# D2522AA register map
Vendor: Dialog; Series: D2522AA; File version: 1.2
CPU: CM0 r1p0, little endian, MPU, FPU, 3 interrupt priority bits
Registers are 32-bit, read-write, reset 0x0 unless marked. A register's access mark holds for its fields unless they carry their own. Offsets are from the block's base; [hi:lo] are bit positions.

## I2C2 — I2C2 registers
Base 0x50020700
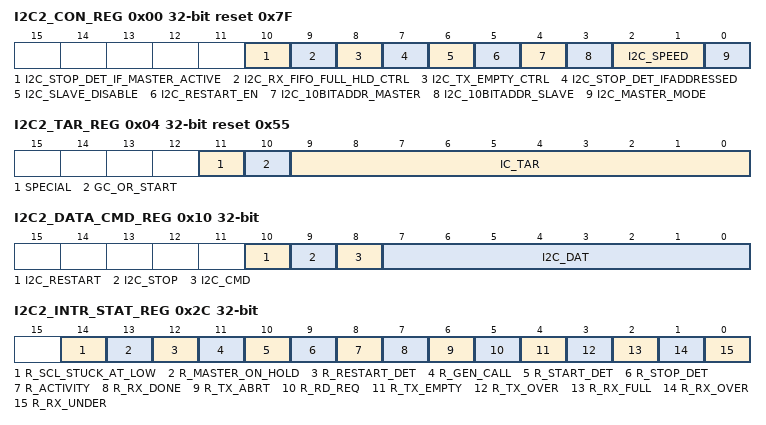
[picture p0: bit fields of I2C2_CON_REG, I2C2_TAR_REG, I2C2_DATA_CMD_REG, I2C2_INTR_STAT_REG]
0x00 I2C2_CON_REG reset 0x7F — I2C Control Register
  [10] I2C_STOP_DET_IF_MASTER_ACTIVE ro — In Master mode: 1 = issues the STOP_DET interrupt only when master is active. 0 = issues the STOP_DET irrespective of whether master is active or not.
  [9] I2C_RX_FIFO_FULL_HLD_CTRL — This bit controls whether DW_apb_i2c should hold the bus when the Rx FIFO is physically full to its RX_BUFFER_DEPTH 1 = Hold bus when RX_FIFO is full 0 = Overflow when RX_FIFO is full
  [8] I2C_TX_EMPTY_CTRL — This bit controls the generation of the TX_EMPTY interrupt, as described in the IC_RAW_INTR_STAT register. 1 = Controlled generation of TX_EMPTY interrupt 0 = Default behaviour of TX_EMPTY interrupt
  [7] I2C_STOP_DET_IFADDRESSED — 1 = slave issues STOP_DET intr only if addressed 0 = slave issues STOP_DET intr always During a general call address, this slave does not issue the STOP_DET interrupt if STOP_DET_IF_ADDRESSED = 1'b1, even if the slave responds to the general call address by generating ACK. The STOP_DET interrupt is generated only when the transmitted address matches the slave address (SAR).
  [6] I2C_SLAVE_DISABLE — Slave enabled or disabled after reset is applied, which means software does not have to configure the slave. 0=slave is enabled 1=slave is disabled Software should ensure that if this bit is written with '0', then bit 0 should also be written with a '0'.
  [5] I2C_RESTART_EN — Determines whether RESTART conditions may be sent when acting as a master 0= disable 1=enable
  [4] I2C_10BITADDR_MASTER — Controls whether the controller starts its transfers in 7- or 10-bit addressing mode when acting as a master. 0= 7-bit addressing 1= 10-bit addressing
  [3] I2C_10BITADDR_SLAVE — When acting as a slave, this bit controls whether the controller responds to 7- or 10-bit addresses. 0= 7-bit addressing 1= 10-bit addressing
  [2:1] I2C_SPEED — These bits control at which speed the controller operates. 1= standard mode (100 kbit/s) 2= fast mode (400 kbit/s) 3= high speed mode
  [0] I2C_MASTER_MODE — This bit controls whether the controller master is enabled. 0= master disabled 1= master enabled Software should ensure that if this bit is written with '1' then bit 6 should also be written with a '1'.
0x04 I2C2_TAR_REG reset 0x55 — I2C Target Address Register
  [11] SPECIAL — On read This bit indicates whether software performs a General Call or START BYTE command. 0 = ignore bit 10 GC_OR_START and use IC_TAR normally 1 = perform special I2C command as specified in GC_OR_START bit On write 1 = Enables programming of GENERAL_CALL or START_BYTE transmission 0 = Disables programming of GENERAL_CALL or START_BYTE transmission
  [10] GC_OR_START — On read If bit 11 (SPECIAL) is set to 1, then this bit indicates whether a General Call or START byte command is to be performed by the controller. 0 = General Call Address - after issuing a General Call, only writes may be performed. Attempting to issue a read command results in setting bit 6 (TX_ABRT) of the IC_RAW_INTR_STAT register. The controller remains in General Call mode until the SPECIAL bit value (bit 11) is cleared. 1 = START BYTE On write 1 = START byte transmission 0 = GENERAL_CALL byte transmission
  [9:0] IC_TAR — This is the target address for any master transaction. When transmitting a General Call, these bits are ignored. To generate a START BYTE, the CPU needs to write only once into these bits. Note: If the IC_TAR and IC_SAR are the same, loopback exists but the FIFOs are shared between master and slave, so full loopback is not feasible. Only one direction loopback mode is supported (simplex), not duplex. A master cannot transmit to itself; it can transmit to only a slave
0x08 I2C2_SAR_REG reset 0x55 — I2C Slave Address Register
  [9:0] IC_SAR — The IC_SAR holds the slave address when the I2C is operating as a slave. For 7-bit addressing, only IC_SAR[6:0] is used. This register can be written only when the I2C interface is disabled, which corresponds to the IC_ENABLE register being set to 0. Writes at other times have no effect.
0x0C I2C2_HS_MADDR_REG reset 0x1 — I2C High Speed Master Mode Code Address Register
  [2:0] I2C_IC_HS_MAR — This bit field holds the value of the I2C HS mode master code. HS-mode master codes are reserved 8-bit codes (00001xxx) that are not used for slave addressing or other purposes. Each master has its unique master code; up to eight high-speed mode masters can be present on the same I2C bus system. Valid values are from 0 to 7. This register can be written only when the I2C interface is disabled, which corresponds to the IC_ENABLE[0] register being set to 0. Writes at other times have no effect.
0x10 I2C2_DATA_CMD_REG — I2C Rx/Tx Data Buffer and Command Register
  [10] I2C_RESTART wo — This bit controls whether a RESTART is issued before the byte is sent or received. 1 = If IC_RESTART_EN is 1, a RESTART is issued before the data is sent/received (according to the value of CMD), regardless of whether or not the transfer direction is changing from the previous command; if IC_RESTART_EN is 0, a STOP followed by a START is issued instead. 0 = If IC_RESTART_EN is 1, a RESTART is issued only if the transfer direction is changing from the previous command; if IC_RESTART_EN is 0, a STOP followed by a START is issued instead.
  [9] I2C_STOP wo — This bit controls whether a STOP is issued after the byte is sent or received. 1 = STOP is issued after this byte, regardless of whether or not the Tx FIFO is empty. If the Tx FIFO is not empty, the master immediately tries to start a new transfer by issuing a START and arbitrating for the bus. 0 = STOP is not issued after this byte, regardless of whether or not the Tx FIFO is empty. If the Tx FIFO is not empty, the master continues the current transfer by sending/receiving data bytes according to the value of the CMD bit. If the Tx FIFO is empty, the master holds the SCL line low and stalls the bus until a new command is available in the Tx FIFO.
  [8] I2C_CMD wo — This bit controls whether a read or a write is performed. This bit does not control the direction when the I2C Ctrl acts as a slave. It controls only the direction when it acts as a master. 1 = Read 0 = Write When a command is entered in the TX FIFO, this bit distinguishes the write and read commands. In slave-receiver mode, this bit is a "don't care" because writes to this register are not required. In slave-transmitter mode, a "0" indicates that CPU data is to be transmitted and as DAT or IC_DATA_CMD[7:0]. When programming this bit, you should remember the following: attempting to perform a read operation after a General Call command has been sent results in a TX_ABRT interrupt (bit 6 of the I2C_RAW_INTR_STAT_REG), unless bit 11 (SPECIAL) in the I2C_TAR register has been cleared. If a "1" is written to this bit after receiving a RD_REQ interrupt, then a TX_ABRT interrupt occurs. NOTE: It is possible that while attempting a master I2C read transfer on the controller, a RD_REQ interrupt may have occurred simultaneously due to a remote I2C master addressing the controller. In this type of scenario, it ignores the I2C_DATA_CMD write, generates a TX_ABRT interrupt, and waits to service the RD_REQ interrupt
  [7:0] I2C_DAT — This register contains the data to be transmitted or received on the I2C bus. If you are writing to this register and want to perform a read, bits 7:0 (DAT) are ignored by the controller. However, when you read this register, these bits return the value of data received on the controller's interface.
0x14 I2C2_SS_SCL_HCNT_REG reset 0x91 — Standard Speed I2C Clock SCL High Count Register
  [15:0] IC_SS_SCL_HCNT — This register must be set before any I2C bus transaction can take place to ensure proper I/O timing. This register sets the SCL clock high-period count for standard speed. This register can be written only when the I2C interface is disabled which corresponds to the IC_ENABLE register being set to 0. Writes at other times have no effect. The minimum valid value is 6; hardware prevents values less than this being written, and if attempted results in 6 being set. NOTE: This register must not be programmed to a value higher than 65525, because the controller uses a 16-bit counter to flag an I2C bus idle condition when this counter reaches a value of IC_SS_SCL_HCNT + 10.
0x18 I2C2_SS_SCL_LCNT_REG reset 0xAB — Standard Speed I2C Clock SCL Low Count Register
  [15:0] IC_SS_SCL_LCNT — This register must be set before any I2C bus transaction can take place to ensure proper I/O timing. This register sets the SCL clock low period count for standard speed. This register can be written only when the I2C interface is disabled which corresponds to the I2C_ENABLE register being set to 0. Writes at other times have no effect. The minimum valid value is 8; hardware prevents values less than this being written, and if attempted, results in 8 being set.
0x1C I2C2_FS_SCL_HCNT_REG reset 0x1A — Fast Speed I2C Clock SCL High Count Register
  [15:0] IC_FS_SCL_HCNT — This register must be set before any I2C bus transaction can take place to ensure proper I/O timing. This register sets the SCL clock high-period count for fast speed. It is used in high-speed mode to send the Master Code and START BYTE or General CALL. This register can be written only when the I2C interface is disabled, which corresponds to the I2C_ENABLE register being set to 0. Writes at other times have no effect. The minimum valid value is 6; hardware prevents values less than this being written, and if attempted results in 6 being set.
0x20 I2C2_FS_SCL_LCNT_REG reset 0x32 — Fast Speed I2C Clock SCL Low Count Register
  [15:0] IC_FS_SCL_LCNT — This register must be set before any I2C bus transaction can take place to ensure proper I/O timing. This register sets the SCL clock low-period count for fast speed. It is used in high-speed mode to send the Master Code and START BYTE or General CALL. This register can be written only when the I2C interface is disabled, which corresponds to the I2C_ENABLE register being set to 0. Writes at other times have no effect. The minimum valid value is 8; hardware prevents values less than this being written, and if attempted results in 8 being set. For designs with APB_DATA_WIDTH = 8 the order of programming is important to ensure the correct operation of the controller. The lower byte must be programmed first. Then the upper byte is programmed.
0x24 I2C2_HS_SCL_HCNT_REG reset 0x6 — High Speed I2C Clock SCL High Count Register
  [15:0] IC_HS_SCL_HCNT — This register must be set before any I2C bus transaction can take place to ensure proper I/O timing. This register sets the SCL clock high period count for high speed.refer to "IC_CLK Frequency Configuration". The SCL High time depends on the loading of the bus. For 100pF loading, the SCL High time is 60ns; for 400pF loading, the SCL High time is 120ns. This register goes away and becomes read-only returning 0s if IC_MAX_SPEED_MODE != high. This register can be written only when the I2C interface is disabled, which corresponds to the IC_ENABLE[0] register being set to 0. Writes at other times have no effect. The minimum valid value is 6; hardware prevents values less than this being written, and if attempted results in 6 being set. For designs with APB_DATA_WIDTH = 8 the order of programming is important to ensure the correct operation of the DW_apb_i2c. The lower byte must be programmed first. Then the upper byte is programmed.
0x28 I2C2_HS_SCL_LCNT_REG reset 0x10 — High Speed I2C Clock SCL Low Count Register
  [15:0] IC_HS_SCL_LCNT — This register must be set before any I2C bus transaction can take place to ensure proper I/O timing. This register sets the SCL clock low period count for high speed. For more information, refer to "IC_CLK Frequency Configuration". The SCL low time depends on the loading of the bus. For 100pF loading, the SCL low time is 160ns; for 400pF loading, the SCL low time is 320ns. This register goes away and becomes read-only returning 0s if IC_MAX_SPEED_MODE != high. This register can be written only when the I2C interface is disabled, which corresponds to the IC_ENABLE[0] register being set to 0. Writes at other times have no effect. The minimum valid value is 8; hardware prevents values less than this being written, and if attempted results in 8 being set. For designs with APB_DATA_WIDTH == 8 the order of programming is important to ensure the correct operation of the DW_apb_i2c. The lower byte must be programmed first. Then the upper byte is programmed. If the value is less than 8 then the count value gets changed to 8.
0x2C I2C2_INTR_STAT_REG — I2C Interrupt Status Register
  [14] R_SCL_STUCK_AT_LOW ro — 1 = R_SCL_STUCK_AT_LOW interrupt is active 0 = R_SCL_STUCK_AT_LOW interrupt is inactive
  [13] R_MASTER_ON_HOLD ro — Indicates whether master is holding the bus and TX FIFO is empty. Enabled only when I2C_DYNAMIC_TAR_UPDATE=1 and IC_EMPTYFIFO_HOLD_MASTER_EN=1.
  [12] R_RESTART_DET ro — Indicates whether a RESTART condition has occurred on the I2C interface when DW_apb_i2c is operating in Slave mode and the slave is being addressed. Enabled only when IC_SLV_RESTART_DET_EN=1. Note: However, in high-speed mode or during a START BYTE transfer, the RESTART comes before the address field as per the I2C protocol. In this case, the slave is not the addressed slave when the RESTART is issued, therefore DW_apb_i2c does not generate the RESTART_DET interrupt.
  [11] R_GEN_CALL ro — Set only when a General Call address is received and it is acknowledged. It stays set until it is cleared either by disabling controller or when the CPU reads bit 0 of the I2C_CLR_GEN_CALL register. The controller stores the received data in the Rx buffer.
  [10] R_START_DET ro — Indicates whether a START or RESTART condition has occurred on the I2C interface regardless of whether controller is operating in slave or master mode.
  [9] R_STOP_DET ro — Indicates whether a STOP condition has occurred on the I2C interface regardless of whether controller is operating in slave or master mode.
  [8] R_ACTIVITY ro — This bit captures I2C Ctrl activity and stays set until it is cleared. There are four ways to clear it: => Disabling the I2C Ctrl => Reading the IC_CLR_ACTIVITY register => Reading the IC_CLR_INTR register => System reset Once this bit is set, it stays set unless one of the four methods is used to clear it. Even if the controller module is idle, this bit remains set until cleared, indicating that there was activity on the bus.
  [7] R_RX_DONE ro — When the controller is acting as a slave-transmitter, this bit is set to 1 if the master does not acknowledge a transmitted byte. This occurs on the last byte of the transmission, indicating that the transmission is done.
  [6] R_TX_ABRT ro — This bit indicates if the controller, as an I2C transmitter, is unable to complete the intended actions on the contents of the transmit FIFO. This situation can occur both as an I2C master or an I2C slave, and is referred to as a "transmit abort". When this bit is set to 1, the I2C_TX_ABRT_SOURCE register indicates the reason why the transmit abort takes places. NOTE: The controller flushes/resets/empties the TX FIFO whenever this bit is set. The TX FIFO remains in this flushed state until the register I2C_CLR_TX_ABRT is read. Once this read is performed, the TX FIFO is then ready to accept more data bytes from the APB interface.
  [5] R_RD_REQ ro — This bit is set to 1 when the controller is acting as a slave and another I2C master is attempting to read data from the controller. The controller holds the I2C bus in a wait state (SCL=0) until this interrupt is serviced, which means that the slave has been addressed by a remote master that is asking for data to be transferred. The processor must respond to this interrupt and then write the requested data to the I2C_DATA_CMD register. This bit is set to 0 just after the processor reads the I2C_CLR_RD_REQ register
  [4] R_TX_EMPTY ro — This bit is set to 1 when the transmit buffer is at or below the threshold value set in the I2C_TX_TL register. It is automatically cleared by hardware when the buffer level goes above the threshold. When the IC_ENABLE bit 0 is 0, the TX FIFO is flushed and held in reset. There the TX FIFO looks like it has no data within it, so this bit is set to 1, provided there is activity in the master or slave state machines. When there is no longer activity, then with ic_en=0, this bit is set to 0.
  [3] R_TX_OVER ro — Set during transmit if the transmit buffer is filled to 32 and the processor attempts to issue another I2C command by writing to the IC_DATA_CMD register. When the module is disabled, this bit keeps its level until the master or slave state machines go into idle, and when ic_en goes to 0, this interrupt is cleared
  [2] R_RX_FULL ro — Set when the receive buffer reaches or goes above the RX_TL threshold in the I2C_RX_TL register. It is automatically cleared by hardware when buffer level goes below the threshold. If the module is disabled (I2C_ENABLE[0]=0), the RX FIFO is flushed and held in reset; therefore the RX FIFO is not full. So this bit is cleared once the I2C_ENABLE bit 0 is programmed with a 0, regardless of the activity that continues.
  [1] R_RX_OVER ro — Set if the receive buffer is completely filled to 32 and an additional byte is received from an external I2C device. The controller acknowledges this, but any data bytes received after the FIFO is full are lost. If the module is disabled (I2C_ENABLE[0]=0), this bit keeps its level until the master or slave state machines go into idle, and when ic_en goes to 0, this interrupt is cleared.
  [0] R_RX_UNDER ro — Set if the processor attempts to read the receive buffer when it is empty by reading from the IC_DATA_CMD register. If the module is disabled (I2C_ENABLE[0]=0), this bit keeps its level until the master or slave state machines go into idle, and when ic_en goes to 0, this interrupt is cleared.
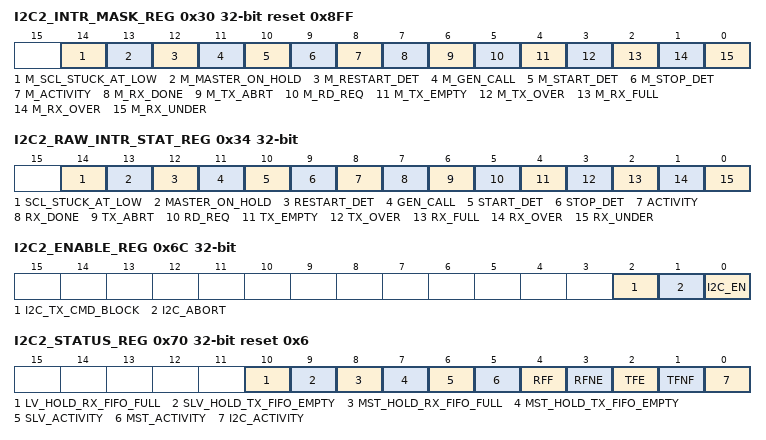
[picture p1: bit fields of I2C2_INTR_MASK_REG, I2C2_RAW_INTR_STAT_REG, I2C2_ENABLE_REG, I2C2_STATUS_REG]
0x30 I2C2_INTR_MASK_REG reset 0x8FF — I2C Interrupt Mask Register
  [14] M_SCL_STUCK_AT_LOW ro — M_SCL_STUCK_AT_LOW Register field Reserved bits
  [13] M_MASTER_ON_HOLD — These bits mask their corresponding interrupt status bits in the I2C_INTR_STAT register.
  [12] M_RESTART_DET — These bits mask their corresponding interrupt status bits in the I2C_INTR_STAT register.
  [11] M_GEN_CALL — These bits mask their corresponding interrupt status bits in the I2C_INTR_STAT register.
  [10] M_START_DET — These bits mask their corresponding interrupt status bits in the I2C_INTR_STAT register.
  [9] M_STOP_DET — These bits mask their corresponding interrupt status bits in the I2C_INTR_STAT register.
  [8] M_ACTIVITY — These bits mask their corresponding interrupt status bits in the I2C_INTR_STAT register.
  [7] M_RX_DONE — These bits mask their corresponding interrupt status bits in the I2C_INTR_STAT register.
  [6] M_TX_ABRT — These bits mask their corresponding interrupt status bits in the I2C_INTR_STAT register.
  [5] M_RD_REQ — These bits mask their corresponding interrupt status bits in the I2C_INTR_STAT register.
  [4] M_TX_EMPTY — These bits mask their corresponding interrupt status bits in the I2C_INTR_STAT register.
  [3] M_TX_OVER — These bits mask their corresponding interrupt status bits in the I2C_INTR_STAT register.
  [2] M_RX_FULL — These bits mask their corresponding interrupt status bits in the I2C_INTR_STAT register.
  [1] M_RX_OVER — These bits mask their corresponding interrupt status bits in the I2C_INTR_STAT register.
  [0] M_RX_UNDER — These bits mask their corresponding interrupt status bits in the I2C_INTR_STAT register.
0x34 I2C2_RAW_INTR_STAT_REG — I2C Raw Interrupt Status Register
  [14] SCL_STUCK_AT_LOW ro — CL_STUCK_AT_LOW Register field Reserved bits
  [13] MASTER_ON_HOLD ro — ndicates whether master is holding the bus and TX FIFO is empty. Enabled only when I2C_DYNAMIC_TAR_UPDATE=1 and IC_EMPTYFIFO_HOLD_MASTER_EN=1.
  [12] RESTART_DET ro — Indicates whether a RESTART condition has occurred on the I2C interface when DW_apb_i2c is operating in Slave mode and the slave is being addressed. Enabled only when IC_SLV_RESTART_DET_EN=1. Note: However, in high-speed mode or during a START BYTE transfer, the RESTART comes before the address field as per the I2C protocol. In this case, the slave is not the addressed slave when the RESTART is issued, therefore DW_apb_i2c does not generate the RESTART_DET interrupt.
  [11] GEN_CALL ro — Set only when a General Call address is received and it is acknowledged. It stays set until it is cleared either by disabling controller or when the CPU reads bit 0 of the I2C_CLR_GEN_CALL register. I2C Ctrl stores the received data in the Rx buffer.
  [10] START_DET ro — Indicates whether a START or RESTART condition has occurred on the I2C interface regardless of whether controller is operating in slave or master mode.
  [9] STOP_DET ro — Indicates whether a STOP condition has occurred on the I2C interface regardless of whether controller is operating in slave or master mode.
  [8] ACTIVITY ro — This bit captures I2C Ctrl activity and stays set until it is cleared. There are four ways to clear it: => Disabling the I2C Ctrl => Reading the IC_CLR_ACTIVITY register => Reading the IC_CLR_INTR register => System reset Once this bit is set, it stays set unless one of the four methods is used to clear it. Even if the controller module is idle, this bit remains set until cleared, indicating that there was activity on the bus.
  [7] RX_DONE ro — When the controller is acting as a slave-transmitter, this bit is set to 1 if the master does not acknowledge a transmitted byte. This occurs on the last byte of the transmission, indicating that the transmission is done.
  [6] TX_ABRT ro — This bit indicates if the controller, as an I2C transmitter, is unable to complete the intended actions on the contents of the transmit FIFO. This situation can occur both as an I2C master or an I2C slave, and is referred to as a "transmit abort". When this bit is set to 1, the I2C_TX_ABRT_SOURCE register indicates the reason why the transmit abort takes places. NOTE: The controller flushes/resets/empties the TX FIFO whenever this bit is set. The TX FIFO remains in this flushed state until the register I2C_CLR_TX_ABRT is read. Once this read is performed, the TX FIFO is then ready to accept more data bytes from the APB interface.
  [5] RD_REQ ro — This bit is set to 1 when I2C Ctrl is acting as a slave and another I2C master is attempting to read data from the controller. The controller holds the I2C bus in a wait state (SCL=0) until this interrupt is serviced, which means that the slave has been addressed by a remote master that is asking for data to be transferred. The processor must respond to this interrupt and then write the requested data to the I2C_DATA_CMD register. This bit is set to 0 just after the processor reads the I2C_CLR_RD_REQ register
  [4] TX_EMPTY ro — This bit is set to 1 when the transmit buffer is at or below the threshold value set in the I2C_TX_TL register. It is automatically cleared by hardware when the buffer level goes above the threshold. When the IC_ENABLE bit 0 is 0, the TX FIFO is flushed and held in reset. There the TX FIFO looks like it has no data within it, so this bit is set to 1, provided there is activity in the master or slave state machines. When there is no longer activity, then with ic_en=0, this bit is set to 0.
  [3] TX_OVER ro — Set during transmit if the transmit buffer is filled to 32 and the processor attempts to issue another I2C command by writing to the IC_DATA_CMD register. When the module is disabled, this bit keeps its level until the master or slave state machines go into idle, and when ic_en goes to 0, this interrupt is cleared
  [2] RX_FULL ro — Set when the receive buffer reaches or goes above the RX_TL threshold in the I2C_RX_TL register. It is automatically cleared by hardware when buffer level goes below the threshold. If the module is disabled (I2C_ENABLE[0]=0), the RX FIFO is flushed and held in reset; therefore the RX FIFO is not full. So this bit is cleared once the I2C_ENABLE bit 0 is programmed with a 0, regardless of the activity that continues.
  [1] RX_OVER ro — Set if the receive buffer is completely filled to 32 and an additional byte is received from an external I2C device. The controller acknowledges this, but any data bytes received after the FIFO is full are lost. If the module is disabled (I2C_ENABLE[0]=0), this bit keeps its level until the master or slave state machines go into idle, and when ic_en goes to 0, this interrupt is cleared.
  [0] RX_UNDER ro — Set if the processor attempts to read the receive buffer when it is empty by reading from the IC_DATA_CMD register. If the module is disabled (I2C_ENABLE[0]=0), this bit keeps its level until the master or slave state machines go into idle, and when ic_en goes to 0, this interrupt is cleared.
0x38 I2C2_RX_TL_REG — I2C Receive FIFO Threshold Register
  [4:0] RX_TL — Receive FIFO Threshold Level Controls the level of entries (or above) that triggers the RX_FULL interrupt (bit 2 in I2C_RAW_INTR_STAT register). The valid range is 0-31, with the additional restriction that hardware does not allow this value to be set to a value larger than the depth of the buffer. If an attempt is made to do that, the actual value set will be the maximum depth of the buffer. A value of 0 sets the threshold for 1 entry, and a value of 31 sets the threshold for 32 entries.
0x3C I2C2_TX_TL_REG — I2C Transmit FIFO Threshold Register
  [4:0] TX_TL — Transmit FIFO Threshold Level Controls the level of entries (or below) that trigger the TX_EMPTY interrupt (bit 4 in I2C_RAW_INTR_STAT register). The valid range is 0-31, with the additional restriction that it may not be set to value larger than the depth of the buffer. If an attempt is made to do that, the actual value set will be the maximum depth of the buffer. A value of 0 sets the threshold for 0 entries, and a value of 31 sets the threshold for 32 entries..
0x40 I2C2_CLR_INTR_REG — Clear Combined and Individual Interrupt Register
  [0] CLR_INTR ro — Read this register to clear the combined interrupt, all individual interrupts, and the I2C_TX_ABRT_SOURCE register. This bit does not clear hardware clearable interrupts but software clearable interrupts. Refer to Bit 9 of the I2C_TX_ABRT_SOURCE register for an exception to clearing I2C_TX_ABRT_SOURCE
0x44 I2C2_CLR_RX_UNDER_REG — Clear RX_UNDER Interrupt Register
  [0] CLR_RX_UNDER ro — Read this register to clear the RX_UNDER interrupt (bit 0) of the I2C_RAW_INTR_STAT register.
0x48 I2C2_CLR_RX_OVER_REG — Clear RX_OVER Interrupt Register
  [0] CLR_RX_OVER ro — Read this register to clear the RX_OVER interrupt (bit 1) of the I2C_RAW_INTR_STAT register.
0x4C I2C2_CLR_TX_OVER_REG — Clear TX_OVER Interrupt Register
  [0] CLR_TX_OVER ro — Read this register to clear the TX_OVER interrupt (bit 3) of the I2C_RAW_INTR_STAT register.
0x50 I2C2_CLR_RD_REQ_REG — Clear RD_REQ Interrupt Register
  [0] CLR_RD_REQ ro — Read this register to clear the RD_REQ interrupt (bit 5) of the I2C_RAW_INTR_STAT register.
0x54 I2C2_CLR_TX_ABRT_REG — Clear TX_ABRT Interrupt Register
  [0] CLR_TX_ABRT ro — Read this register to clear the TX_ABRT interrupt (bit 6) of the IC_RAW_INTR_STAT register, and the I2C_TX_ABRT_SOURCE register. This also releases the TX FIFO from the flushed/reset state, allowing more writes to the TX FIFO. Refer to Bit 9 of the I2C_TX_ABRT_SOURCE register for an exception to clearing IC_TX_ABRT_SOURCE.
0x58 I2C2_CLR_RX_DONE_REG — Clear RX_DONE Interrupt Register
  [0] CLR_RX_DONE ro — Read this register to clear the RX_DONE interrupt (bit 7) of the I2C_RAW_INTR_STAT register.
0x5C I2C2_CLR_ACTIVITY_REG — Clear ACTIVITY Interrupt Register
  [0] CLR_ACTIVITY ro — Reading this register clears the ACTIVITY interrupt if the I2C is not active anymore. If the I2C module is still active on the bus, the ACTIVITY interrupt bit continues to be set. It is automatically cleared by hardware if the module is disabled and if there is no further activity on the bus. The value read from this register to get status of the ACTIVITY interrupt (bit 8) of the IC_RAW_INTR_STAT register
0x60 I2C2_CLR_STOP_DET_REG — Clear STOP_DET Interrupt Register
  [0] CLR_ACTIVITY ro — Reading this register clears the ACTIVITY interrupt if the I2C is not active anymore. If the I2C module is still active on the bus, the ACTIVITY interrupt bit continues to be set. It is automatically cleared by hardware if the module is disabled and if there is no further activity on the bus. The value read from this register to get status of the ACTIVITY interrupt (bit 8) of the IC_RAW_INTR_STAT register.
0x64 I2C2_CLR_START_DET_REG — Clear START_DET Interrupt Register
  [0] CLR_START_DET ro — Read this register to clear the START_DET interrupt (bit 10) of the IC_RAW_INTR_STAT register.
0x68 I2C2_CLR_GEN_CALL_REG — Clear GEN_CALL Interrupt Register
  [0] CLR_GEN_CALL ro — Read this register to clear the GEN_CALL interrupt (bit 11) of I2C_RAW_INTR_STAT register.
0x6C I2C2_ENABLE_REG — I2C Enable Register
  [2] I2C_TX_CMD_BLOCK — In Master mode: 1 = Blocks the transmission of data on I2C bus even if Tx FIFO has data to transmit. 0.= The transmission of data starts on I2C bus automatically, as soon as the first data is available in the Tx FIFO.
  [1] I2C_ABORT — The software can abort the I2C transfer in master mode by setting this bit. The software can set this bit only when ENABLE is already set; otherwise, the controller ignores any write to ABORT bit. The software cannot clear the ABORT bit once set. In response to an ABORT, the controller issues a STOP and flushes the Tx FIFO after completing the current transfer, then sets the TX_ABORT interrupt after the abort operation. The ABORT bit is cleared automatically after the abort operation.
  [0] I2C_EN — Controls whether the controller is enabled. 0 = Disables the controller (TX and RX FIFOs are held in an erased state) 1 = Enables the controller Software can disable the controller while it is active. However, it is important that care be taken to ensure that the controller is disabled properly. When the controller is disabled, the following occurs: * The TX FIFO and RX FIFO get flushed. * Status bits in the IC_INTR_STAT register are still active until the controller goes into IDLE state. If the module is transmitting, it stops as well as deletes the contents of the transmit buffer after the current transfer is complete. If the module is receiving, the controller stops the current transfer at the end of the current byte and does not acknowledge the transfer. There is a two ic_clk delay when enabling or disabling the controller
0x70 I2C2_STATUS_REG reset 0x6 — I2C Status Register
  [10] LV_HOLD_RX_FIFO_FULL ro — This bit indicates the BUS Hold in Slave mode due to Rx FIFO is Full and an additional byte has been received 1 = Slave holds the bus due to Rx FIFO is full 0 = Slave is not holding the bus or Bus hold is not due to Rx FIFO is full
  [9] SLV_HOLD_TX_FIFO_EMPTY ro — This bit indicates the BUS Hold in Slave mode for the Read request when the Tx FIFO is empty. The Bus is in hold until the Tx FIFO has data to Transmit for the read request. 1 = Slave holds the bus due to Tx FIFO is empty 0 = Slave is not holding the bus or Bus hold is not due to Tx FIFO is empty
  [8] MST_HOLD_RX_FIFO_FULL ro — This bit indicates the BUS Hold in Master mode due to Rx FIFO is Full and additional byte has been received 1 = Master holds the bus due to Rx FIFO is full 0 = Master is not holding the bus or Bus hold is not due to Rx FIFO is full
  [7] MST_HOLD_TX_FIFO_EMPTY ro — the DW_apb_i2c master stalls the write transfer when Tx FIFO is empty, and the the last byte does not have the Stop bit set. This bit indicates the BUS hold when the master holds the bus because of the Tx FIFO being empty, and the the previous transferred command does not have the Stop bit set. 1 =Master holds the bus due to Tx FIFO is empty 0 =Master is not holding the bus or Bus hold is not due to Tx FIFO is empty
  [6] SLV_ACTIVITY ro — Slave FSM Activity Status. When the Slave Finite State Machine (FSM) is not in the IDLE state, this bit is set. 0 = Slave FSM is in IDLE state so the Slave part of the controller is not Active 1 = Slave FSM is not in IDLE state so the Slave part of the controller is Active
  [5] MST_ACTIVITY ro — Master FSM Activity Status. When the Master Finite State Machine (FSM) is not in the IDLE state, this bit is set. 0 = Master FSM is in IDLE state so the Master part of the controller is not Active 1 = Master FSM is not in IDLE state so the Master part of the controller is Active
  [4] RFF ro — Receive FIFO Completely Full. When the receive FIFO is completely full, this bit is set. When the receive FIFO contains one or more empty location, this bit is cleared. 0 = Receive FIFO is not full 1 = Receive FIFO is full
  [3] RFNE ro — Receive FIFO Not Empty. This bit is set when the receive FIFO contains one or more entries; it is cleared when the receive FIFO is empty. 0 = Receive FIFO is empty 1 = Receive FIFO is not empty
  [2] TFE ro — Transmit FIFO Completely Empty. When the transmit FIFO is completely empty, this bit is set. When it contains one or more valid entries, this bit is cleared. This bit field does not request an interrupt. 0 = Transmit FIFO is not empty 1 = Transmit FIFO is empty
  [1] TFNF ro — Transmit FIFO Not Full. Set when the transmit FIFO contains one or more empty locations, and is cleared when the FIFO is full. 0 = Transmit FIFO is full 1 = Transmit FIFO is not full
  [0] I2C_ACTIVITY ro — I2C Activity Status.
0x74 I2C2_TXFLR_REG — I2C Transmit FIFO Level Register
  [5:0] TXFLR ro — Transmit FIFO Level. Contains the number of valid data entries in the transmit FIFO. Size is constrained by the TXFLR value
0x78 I2C2_RXFLR_REG — I2C Receive FIFO Level Register
  [5:0] RXFLR ro — Receive FIFO Level. Contains the number of valid data entries in the receive FIFO. Size is constrained by the RXFLR value
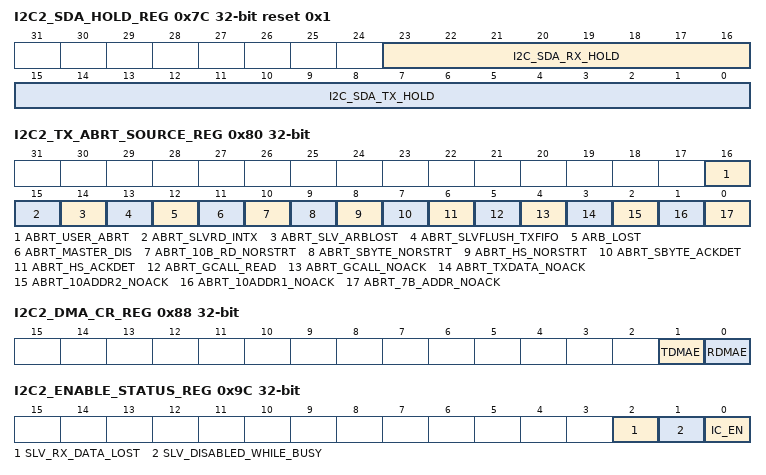
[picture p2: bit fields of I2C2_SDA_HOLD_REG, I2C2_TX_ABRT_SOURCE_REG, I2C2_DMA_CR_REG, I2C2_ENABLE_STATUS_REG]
0x7C I2C2_SDA_HOLD_REG reset 0x1 — I2C SDA Hold Time Length Register
  [23:16] I2C_SDA_RX_HOLD — Sets the required SDA hold time in units of ic_clk period, when receiver.
  [15:0] I2C_SDA_TX_HOLD — Sets the required SDA hold time in units of ic_clk period, when transmitter.
0x80 I2C2_TX_ABRT_SOURCE_REG — I2C Transmit Abort Source Register
  [16] ABRT_USER_ABRT ro — Master-Transmitter : This is a master-mode-only bit. Master has detected the transfer abort (IC_ENABLE[1])
  [15] ABRT_SLVRD_INTX ro — Slave-Transmitter : When the processor side responds to a slave mode request for data to be transmitted to a remote master and user writes a 1 in CMD (bit 8) of 2IC_DATA_CMD register 1 = Slave trying to transmit to remote master in read mode 0 = Slave trying to transmit to remote master in read mode- scenario not present
  [14] ABRT_SLV_ARBLOST ro — Slave-Transmitter : Slave lost the bus while transmitting data to a remote master. I2C_TX_ABRT_SOURCE[12] is set at the same time. Note: Even though the slave never "owns" the bus, something could go wrong on the bus. This is a fail safe check. For instance, during a data transmission at the low-to-high transition of SCL, if what is on the data bus is not what is supposed to be transmitted, then the controller no longer own the bus. 1 = Slave lost arbitration to remote master 0 = Slave lost arbitration to remote master- scenario not present
  [13] ABRT_SLVFLUSH_TXFIFO ro — Slave-Transmitter : Slave has received a read command and some data exists in the TX FIFO so the slave issues a TX_ABRT interrupt to flush old data in TX FIFO. 1 = Slave flushes existing data in TX-FIFO upon getting read command 0 = Slave flushes existing data in TX-FIFO upon getting read command- scenario not present
  [12] ARB_LOST ro — Master-Transmitter or Slave-Transmitter : Master has lost arbitration, or if I2C_TX_ABRT_SOURCE[14] is also set, then the slave transmitter has lost arbitration. Note: I2C can be both master and slave at the same time. 1 = Master or Slave-Transmitter lost arbitration 0 = Master or Slave-Transmitter lost arbitration- scenario not present
  [11] ABRT_MASTER_DIS ro — Master-Transmitter or Master-Receiver : User tries to initiate a Master operation with the Master mode disabled. 1 = User intitating master operation when MASTER disable 0 = User initiating master operation when MASTER disabled- scenario not present
  [10] ABRT_10B_RD_NORSTRT ro — Master-Receiver : The restart is disabled (IC_RESTART_EN bit (I2C_CON[5]) = 0) and the master sends a read command in 10-bit addressing mode. 1 =Master trying to read in 10Bit addressing mode when RESTART disabled 0 =Master not trying to read in 10Bit addressing mode when RESTART disabled
  [9] ABRT_SBYTE_NORSTRT ro — Master : To clear Bit 9, the source of the ABRT_SBYTE_NORSTRT must be fixed first; restart must be enabled (I2C_CON[5]=1), the SPECIAL bit must be cleared (I2C_TAR[11]), or the GC_OR_START bit must be cleared (I2C_TAR[10]). Once the source of the ABRT_SBYTE_NORSTRT is fixed, then this bit can be cleared in the same manner as other bits in this register. If the source of the ABRT_SBYTE_NORSTRT is not fixed before attempting to clear this bit, bit 9 clears for one cycle and then gets re-asserted. 1: The restart is disabled (IC_RESTART_EN bit (I2C_CON[5]) = 0) and the user is trying to send a START Byte. 1 = User trying to send START byte when RESTART disabled 0 = User trying to send START byte when RESTART disabled- scenario not present
  [8] ABRT_HS_NORSTRT ro — Master-Transmitter or Master-Receiver : The restart is disabled (IC_RESTART_EN bit (I2C_CON[5]) = 0) and the user is trying to use the master to transfer data in High Speed mode 1 = User trying to switch Master to HS mode when RESTART disabled 0 = User trying to switch Master to HS mode when RESTART disabled- scenario not present
  [7] ABRT_SBYTE_ACKDET ro — Master : Master has sent a START Byte and the START Byte was acknowledged (wrong behavior). 1 = ACK detected for START byte 0 = ACK detected for START byte- scenario not present
  [6] ABRT_HS_ACKDET ro — Master : Master is in High Speed mode and the High Speed Master code was acknowledged (wrong behavior). 1 = HS Master code ACKed in HS Mode 0 = HS Master code ACKed in HS Mode- scenario not present
  [5] ABRT_GCALL_READ ro — Master-Transmitter : The controller in master mode sent a General Call but the user programmed the byte following the General Call to be a read from the bus (IC_DATA_CMD[9] is set to 1). 1 = GCALL is followed by read from bus 0 = GCALL is followed by read from bus-scenario not present
  [4] ABRT_GCALL_NOACK ro — Master-Transmitter : the controller in master mode sent a General Call and no slave on the bus acknowledged the General Call. 1 = GCALL not ACKed by any slave 0 = GCALL not ACKed by any slave-scenario not present
  [3] ABRT_TXDATA_NOACK ro — Master-Transmitter : This is a master-mode only bit. Master has received an acknowledgement for the address, but when it sent data byte(s) following the address, it did not receive an acknowledge from the remote slave(s). 1 = Transmitted data not ACKed by addressed slave 0 = Transmitted data non-ACKed by addressed slave-scenario not present
  [2] ABRT_10ADDR2_NOACK ro — Master-Transmitter or Master-Receiver : Master is in 10-bit address mode and the second address byte of the 10-bit address was not acknowledged by any slave. 1= Byte 2 of 10Bit Address not ACKed by any slave 0 = This abort is not generated
  [1] ABRT_10ADDR1_NOACK ro — Master-Transmitter or Master-Receiver : Master is in 10-bit address mode and the first 10-bit address byte was not acknowledged by any slave. 1 =Byte 1 of 10Bit Address not ACKed by any slave 0 =This abort is not generated
  [0] ABRT_7B_ADDR_NOACK ro — Master-Transmitter or Master-Receiver : Master is in 7-bit addressing mode and the address sent was not acknowledged by any slave. 1 =This abort is generated because of NOACK for 7-bit address 0 =This abort is not generated
0x88 I2C2_DMA_CR_REG — DMA Control Register
  [1] TDMAE — Transmit DMA Enable. //This bit enables/disables the transmit FIFO DMA channel. 0 = Transmit DMA disabled 1 = Transmit DMA enabled
  [0] RDMAE — Receive DMA Enable. This bit enables/disables the receive FIFO DMA channel. 0 = Receive DMA disabled 1 = Receive DMA enabled
0x8C I2C2_DMA_TDLR_REG — DMA Transmit Data Level Register
  [4:0] DMATDL — Transmit Data Level. This bit field controls the level at which a DMA request is made by the transmit logic. It is equal to the watermark level; that is, the dma_tx_req signal is generated when the number of valid data entries in the transmit FIFO is equal to or below this field value, and TDMAE = 1.
0x90 I2C2_DMA_RDLR_REG — I2C Receive Data Level Register
  [4:0] DMARDL — Receive Data Level. This bit field controls the level at which a DMA request is made by the receive logic. The watermark level = DMARDL+1; that is, dma_rx_req is generated when the number of valid data entries in the receive FIFO is equal to or more than this field value + 1, and RDMAE =1. For instance, when DMARDL is 0, then dma_rx_req is asserted when 1 or more data entries are present in the receive FIFO.
0x94 I2C2_SDA_SETUP_REG reset 0x64 — I2C SDA Setup Register
  [7:0] SDA_SETUP — SDA Setup. This register controls the amount of time delay (number of I2C clock periods) between the rising edge of SCL and SDA changing by holding SCL low when I2C block services a read request while operating as a slave-transmitter. The relevant I2C requirement is tSU:DAT (note 4) as detailed in the I2C Bus Specification. This register must be programmed with a value equal to or greater than 2. It is recommended that if the required delay is 1000ns, then for an I2C frequency of 10 MHz, IC_SDA_SETUP should be programmed to a value of 11.Writes to this register succeed only when IC_ENABLE[0] = 0.
0x98 I2C2_ACK_GENERAL_CALL_REG — I2C ACK General Call Register
  [0] ACK_GEN_CALL — ACK General Call. When set to 1, I2C Ctrl responds with a ACK (by asserting ic_data_oe) when it receives a General Call. When set to 0, the controller does not generate General Call interrupts. 1 = Generate ACK for a General Call 0 = Generate NACK for General Call
0x9C I2C2_ENABLE_STATUS_REG — I2C Enable Status Register
  [2] SLV_RX_DATA_LOST ro — Slave Received Data Lost. This bit indicates if a Slave-Receiver operation has been aborted with at least one data byte received from an I2C transfer due to the setting of IC_ENABLE from 1 to 0. When read as 1, the controller is deemed to have been actively engaged in an aborted I2C transfer (with matching address) and the data phase of the I2C transfer has been entered, even though a data byte has been responded with a NACK. NOTE: If the remote I2C master terminates the transfer with a STOP condition before the controller has a chance to NACK a transfer, and IC_ENABLE has been set to 0, then this bit is also set to 1. When read as 0, the controller is deemed to have been disabled without being actively involved in the data phase of a Slave-Receiver transfer. NOTE: The CPU can safely read this bit when IC_EN (bit 0) is read as 0. 1 = Slave RX Data is lost 0 = Slave RX Data is not lost
  [1] SLV_DISABLED_WHILE_BUSY ro — Slave Disabled While Busy (Transmit, Receive). This bit indicates if a potential or active Slave operation has been aborted due to the setting of the IC_ENABLE register from 1 to 0. This bit is set when the CPU writes a 0 to the IC_ENABLE register while: (a) I2C Ctrl is receiving the address byte of the Slave-Transmitter operation from a remote master; OR, (b) address and data bytes of the Slave-Receiver operation from a remote master. When read as 1, the controller is deemed to have forced a NACK during any part of an I2C transfer, irrespective of whether the I2C address matches the slave address set in I2C Ctrl (IC_SAR register) OR if the transfer is completed before IC_ENABLE is set to 0 but has not taken effect. NOTE: If the remote I2C master terminates the transfer with a STOP condition before the the controller has a chance to NACK a transfer, and IC_ENABLE has been set to 0, then this bit will also be set to 1. When read as 0, the controller is deemed to have been disabled when there is master activity, or when the I2C bus is idle. NOTE: The CPU can safely read this bit when IC_EN (bit 0) is read as 0. 1 =Slave is disabled when it is active 0 =Slave is disabled when it is idle
  [0] IC_EN ro — ic_en Status. This bit always reflects the value driven on the output port ic_en. When read as 1, the controller is deemed to be in an enabled state. When read as 0, the controller is deemed completely inactive. NOTE: The CPU can safely read this bit anytime. When this bit is read as 0, the CPU can safely read SLV_RX_DATA_LOST (bit 2) and SLV_DISABLED_WHILE_BUSY (bit 1). 1 = I2C enabled 0 =I2C disabled
0xA0 I2C2_IC_FS_SPKLEN_REG reset 0x1 — I2C SS and FS spike suppression limit Size
  [7:0] I2C_FS_SPKLEN — This register must be set before any I2C bus transaction can take place to ensure stable operation. This register sets the duration, measured in ic_clk cycles, of the longest spike in the SCL or SDA lines that will be filtered out by the spike suppression logic. This register can be written only when the I2C interface is disabled which corresponds to the IC_ENABLE register being set to 0. Writes at other times have no effect. The minimum valid value is 1; hardware prevents values less than this being written, and if attempted results in 1 being set.
0xA4 I2C2_IC_HS_SPKLEN_REG reset 0x1 — I2C HS spike suppression limit Size
  [7:0] I2C_HS_SPKLEN — This register must be set before any I2C bus transaction can take place to ensure stable operation. This register sets the duration, measured in ic_clk cycles, of the longest spike in the SCL or SDA lines that will be filtered out by the spike suppression logic. This register can be written only when the I2C interface is disabled which corresponds to the IC_ENABLE[0] register being set to 0. Writes at other times have no effect. The minimum valid value is 1; hardware prevents values less than this being written, and if attempted results in 1 being set.
0xF4 I2C2_COMP_PARAM1_REG (reset mask 0x7FFFFFFF) — Component Parameter Register
  [31:0] IC_COMP_PARAM1 ro — This is a constant read-only register that contains encoded information about the component's parameter settings.
0xF8 I2C2_COMP_VERSION_REG reset 0x3230322A (reset mask 0x7FFFFFFF) — I2C Component Version Register
  [31:0] IC_COMP_VERSION ro
0xFC I2C2_COMP_TYPE_REG reset 0x44570140 (reset mask 0x7FFFFFFF) — I2C Component Type Register
  [31:0] IC_COMP_TYPE ro
